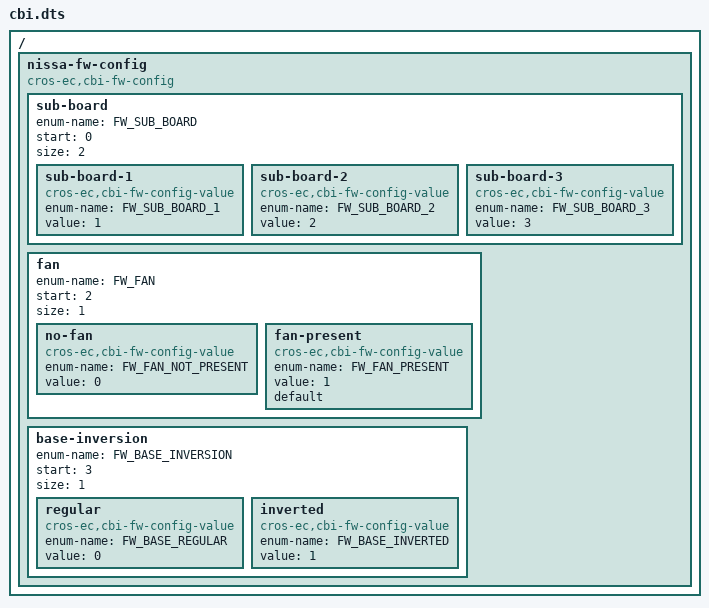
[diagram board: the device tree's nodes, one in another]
/* Copyright 2022 The Chromium OS Authors. All rights reserved.
 * Use of this source code is governed by a BSD-style license that can be
 * found in the LICENSE file.
 */

/ {
	nissa-fw-config {
		compatible = "cros-ec,cbi-fw-config";

		/*
		 * FW_CONFIG field to indicate which sub-board
		 * is attached.
		 */
		sub-board {
			enum-name = "FW_SUB_BOARD";
			start = <0>;
			size = <2>;

			sub-board-1 {
				compatible = "cros-ec,cbi-fw-config-value";
				enum-name = "FW_SUB_BOARD_1";
				value = <1>;
			};
			sub-board-2 {
				compatible = "cros-ec,cbi-fw-config-value";
				enum-name = "FW_SUB_BOARD_2";
				value = <2>;
			};
			sub-board-3 {
				compatible = "cros-ec,cbi-fw-config-value";
				enum-name = "FW_SUB_BOARD_3";
				value = <3>;
			};
		};

		/*
		 * FW_CONFIG field to enable fan or not.
		 */
		fan {
			enum-name = "FW_FAN";
			start = <2>;
			size = <1>;

			no-fan {
				compatible = "cros-ec,cbi-fw-config-value";
				enum-name = "FW_FAN_NOT_PRESENT";
				value = <0>;
			};
			fan-present {
				compatible = "cros-ec,cbi-fw-config-value";
				enum-name = "FW_FAN_PRESENT";
				value = <1>;
				/*
				 * Set as default so that unprovisioned
				 * configs will run the fan regardless.
				 */
				default;
			};
		};

		/*
		 * FW_CONFIG field to describe mainboard orientation in chassis.
		 */
		base-inversion {
			enum-name = "FW_BASE_INVERSION";
			start = <3>;
			size = <1>;

			regular {
				compatible = "cros-ec,cbi-fw-config-value";
				enum-name = "FW_BASE_REGULAR";
				value = <0>;
			};
			inverted {
				compatible = "cros-ec,cbi-fw-config-value";
				enum-name = "FW_BASE_INVERTED";
				value = <1>;
			};
		};
	};
};
